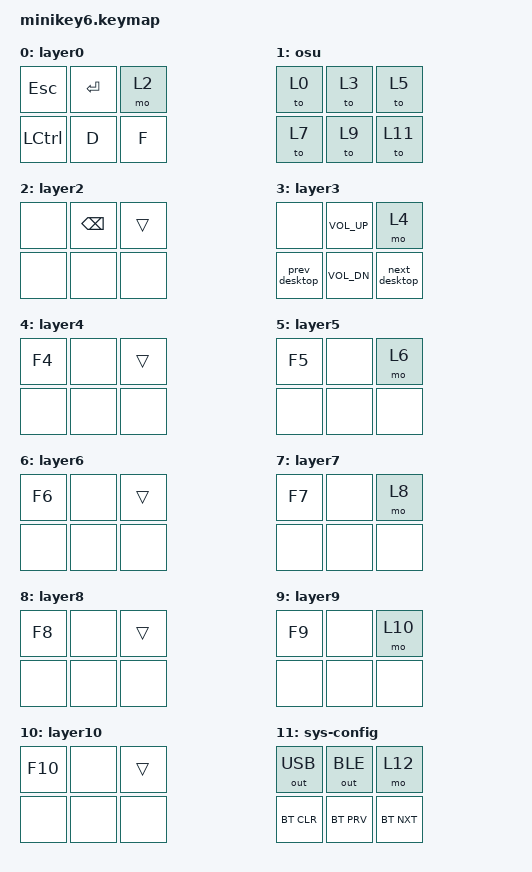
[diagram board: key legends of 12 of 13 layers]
#include <behaviors.dtsi>
#include <dt-bindings/zmk/bt.h>
#include <dt-bindings/zmk/keys.h>
#include <dt-bindings/zmk/outputs.h>

/ {
    macros {
        prev_desktop: prev_desktop {
            compatible = "zmk,behavior-macro";
            #binding-cells = <0>;
            bindings = <&kp LC(LG(LEFT))>;
            label = "PREV_DESKTOP";
        };

        next_desktop: next_desktop {
            compatible = "zmk,behavior-macro";
            #binding-cells = <0>;
            bindings = <&kp LC(LG(RIGHT))>;
            label = "NEXT_DESKTOP";
        };
    };

    combos {
        compatible = "zmk,combos";

        layer_picker {
            bindings = <&to 1>;
            key-positions = <0 1>;
            layers = <2 4 6 8 10 12>;
        };
    };

    keymap {
        compatible = "zmk,keymap";

        layer0 {
            bindings = <
&kp ESC    &kp ENTER  &mo 2
&kp LCTRL  &kp D      &kp F
            >;
        };

        // layer 1

        osu {
            bindings = <
&to 0  &to 3  &to 5
&to 7  &to 9  &to 11
            >;
        };

        // layer 2

        layer2 {
            bindings = <
&none  &kp BSPC  &trans
&none  &none     &none
            >;
        };

        // layer 3

        layer3 {
            bindings = <
&none          &kp C_VOL_UP  &mo 4
&prev_desktop  &kp C_VOL_DN  &next_desktop
            >;
        };

        // layer 4

        layer4 {
            bindings = <
&kp F4  &none  &trans
&none   &none  &none
            >;
        };

        // layer 5

        layer5 {
            bindings = <
&kp F5  &none  &mo 6
&none   &none  &none
            >;
        };

        // layer 6

        layer6 {
            bindings = <
&kp F6  &none  &trans
&none   &none  &none
            >;
        };

        // layer 7

        layer7 {
            bindings = <
&kp F7  &none  &mo 8
&none   &none  &none
            >;
        };

        // layer 8

        layer8 {
            bindings = <
&kp F8  &none  &trans
&none   &none  &none
            >;
        };

        // layer 9

        layer9 {
            bindings = <
&kp F9  &none  &mo 10
&none   &none  &none
            >;
        };

        // layer 10

        layer10 {
            bindings = <
&kp F10  &none  &trans
&none    &none  &none
            >;
        };

        // layer 11

        sys-config {
            bindings = <
&out OUT_USB  &out OUT_BLE  &mo 12
&bt BT_CLR    &bt BT_PRV    &bt BT_NXT
            >;
        };

        // layer 12

        layer12 {
            bindings = <
&kp F12     &none  &trans
&sys_reset  &none  &none
            >;
        };
    };
};
